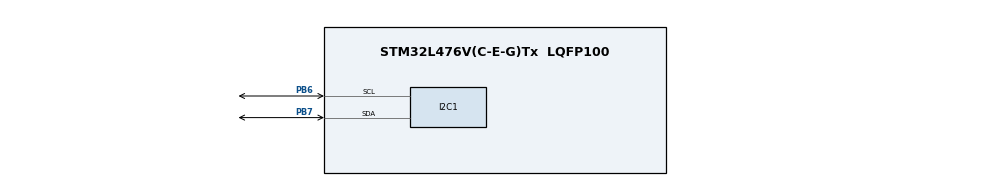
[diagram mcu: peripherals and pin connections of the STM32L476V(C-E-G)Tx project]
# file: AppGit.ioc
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Mcu.Family=STM32L4
Mcu.Name=STM32L476V(C-E-G)Tx
Mcu.Package=LQFP100
NVIC.I2C1_ER_IRQn=true\:0\:0\:false\:false\:true\:true\:true
NVIC.I2C1_EV_IRQn=true\:0\:0\:false\:false\:true\:true\:true
NVIC.PriorityGroup=NVIC_PRIORITYGROUP_4
PB6.GPIO_PuPdOD=GPIO_NOPULL
PB6.Mode=I2C
PB6.Signal=I2C1_SCL
PB7.GPIO_PuPdOD=GPIO_NOPULL
PB7.Mode=I2C
PB7.Signal=I2C1_SDA
ProjectManager.HeapSize=0x200
ProjectManager.StackSize=0x400
ProjectManager.TargetToolchain=EWARM V8.32
RCC.HSE_VALUE=8000000
RCC.HSI_VALUE=16000000
RCC.LSE_VALUE=32768
RCC.MSI_VALUE=4000000
RCC.VCOOutputFreq_Value=32000000
board=custom

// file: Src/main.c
/* USER CODE BEGIN Header */
/**
  ******************************************************************************
  * @file           : main.c
  * @brief          : Main program body
  ******************************************************************************
  * @attention
  *
  * <h2><center>&copy; Copyright (c) 2019 STMicroelectronics.
  * All rights reserved.</center></h2>
  *
  * This software component is licensed by ST under BSD 3-Clause license,
  * the "License"; You may not use this file except in compliance with the
  * License. You may obtain a copy of the License at:
  *                        opensource.org/licenses/BSD-3-Clause
  *
  ******************************************************************************
  */
/* USER CODE END Header */

#include "main.h"

/* USER CODE BEGIN Includes */
#include "bmp280.h"
/* USER CODE END Includes */

/* USER CODE BEGIN PD */
#define BMP280_I2C_ADDRESS_0 0x76
#define BMP280_I2C_ADDRESS_1 0x77
/* USER CODE END PD */

I2C_HandleTypeDef hi2c1;

/* USER CODE BEGIN PV */
BMP280_HandleTypedef bmp280;

float pressure, temperature, humidity;

uint16_t size;
uint8_t Data[256];

bool bme280p;
/* USER CODE END PV */

void SystemClock_Config(void);
static void MX_GPIO_Init(void);
static void MX_I2C1_Init(void);
/* USER CODE BEGIN PFP */
static void MX_BMP_Init(void);
/* USER CODE END PFP */

int main(void)
{

  /* MCU Configuration--------------------------------------------------------*/

  /* Reset of all peripherals, Initializes the Flash interface and the Systick. */
  HAL_Init();

  /* Configure the system clock */
  SystemClock_Config();

  /* Initialize all configured peripherals */
  MX_GPIO_Init();
  MX_I2C1_Init();
  /* USER CODE BEGIN 2 */
  MX_BMP_Init();

  /* USER CODE END 2 */

  /* Infinite loop */
  while (1)
  {
    if (!bmp280_read_float_it(&bmp280, &temperature, &pressure, &humidity))
    {
//      printf("Temperature/pressure reading failed\n");
    }
    printf("     Temperature: %.2f \n Pressure : %.2f Pa\n Humidity: %.2f \n", temperature , pressure , humidity);
    HAL_Delay(2000);
    printf("\n");
  }
}
void SystemClock_Config(void)
{
  RCC_OscInitTypeDef RCC_OscInitStruct = {0};
  RCC_ClkInitTypeDef RCC_ClkInitStruct = {0};
  RCC_PeriphCLKInitTypeDef PeriphClkInit = {0};

  /** Initializes the CPU, AHB and APB busses clocks
  */
  RCC_OscInitStruct.OscillatorType = RCC_OSCILLATORTYPE_MSI;
  RCC_OscInitStruct.MSIState = RCC_MSI_ON;
  RCC_OscInitStruct.MSICalibrationValue = 0;
  RCC_OscInitStruct.MSIClockRange = RCC_MSIRANGE_6;
  RCC_OscInitStruct.PLL.PLLState = RCC_PLL_NONE;
  if (HAL_RCC_OscConfig(&RCC_OscInitStruct) != HAL_OK)
  {
    Error_Handler();
  }
  /** Initializes the CPU, AHB and APB busses clocks
  */
  RCC_ClkInitStruct.ClockType = RCC_CLOCKTYPE_HCLK|RCC_CLOCKTYPE_SYSCLK
                              |RCC_CLOCKTYPE_PCLK1|RCC_CLOCKTYPE_PCLK2;
  RCC_ClkInitStruct.SYSCLKSource = RCC_SYSCLKSOURCE_MSI;
  RCC_ClkInitStruct.AHBCLKDivider = RCC_SYSCLK_DIV1;
  RCC_ClkInitStruct.APB1CLKDivider = RCC_HCLK_DIV1;
  RCC_ClkInitStruct.APB2CLKDivider = RCC_HCLK_DIV1;

  if (HAL_RCC_ClockConfig(&RCC_ClkInitStruct, FLASH_LATENCY_0) != HAL_OK)
  {
    Error_Handler();
  }
  PeriphClkInit.PeriphClockSelection = RCC_PERIPHCLK_I2C1;
  PeriphClkInit.I2c1ClockSelection = RCC_I2C1CLKSOURCE_PCLK1;
  if (HAL_RCCEx_PeriphCLKConfig(&PeriphClkInit) != HAL_OK)
  {
    Error_Handler();
  }
  /** Configure the main internal regulator output voltage
  */
  if (HAL_PWREx_ControlVoltageScaling(PWR_REGULATOR_VOLTAGE_SCALE1) != HAL_OK)
  {
    Error_Handler();
  }
}

static void MX_I2C1_Init(void)
{

  hi2c1.Instance = I2C1;
  hi2c1.Init.Timing = 0x00000E14;
  hi2c1.Init.OwnAddress1 = 0;
  hi2c1.Init.AddressingMode = I2C_ADDRESSINGMODE_7BIT;
  hi2c1.Init.DualAddressMode = I2C_DUALADDRESS_DISABLE;
  hi2c1.Init.OwnAddress2 = 0;
  hi2c1.Init.OwnAddress2Masks = I2C_OA2_NOMASK;
  hi2c1.Init.GeneralCallMode = I2C_GENERALCALL_DISABLE;
  hi2c1.Init.NoStretchMode = I2C_NOSTRETCH_DISABLE;
  if (HAL_I2C_Init(&hi2c1) != HAL_OK)
  {
    Error_Handler();
  }
  /** Configure Analogue filter
  */
  if (HAL_I2CEx_ConfigAnalogFilter(&hi2c1, I2C_ANALOGFILTER_ENABLE) != HAL_OK)
  {
    Error_Handler();
  }
  /** Configure Digital filter
  */
  if (HAL_I2CEx_ConfigDigitalFilter(&hi2c1, 0) != HAL_OK)
  {
    Error_Handler();
  }

}

static void MX_GPIO_Init(void)
{

  /* GPIO Ports Clock Enable */
  __HAL_RCC_GPIOB_CLK_ENABLE();

}

/* USER CODE BEGIN 4 */
static void MX_BMP_Init(void)
{
  bmp280_init_default_params(&bmp280.params);
  bmp280.addr = BMP280_I2C_ADDRESS_1;
  bmp280.i2c = &hi2c1;

  while (!bmp280_init(&bmp280, &bmp280.params))
  {
    printf("BMP280 initialization failed\n");
    HAL_Delay(2000);
  }
  bme280p = bmp280.id == BMP280_CHIP_ID;
  if (bme280p == true)
  {
    printf("BMP280: found BMP280\n");
  }
  else
  {
    printf("BMP280: found BME280\n");
  }
}

//void I2C1_EV_IRQHandler(void)
//{
//  /* USER CODE BEGIN I2C1_EV_IRQn 0 */
//
//  /* USER CODE END I2C1_EV_IRQn 0 */
//  HAL_I2C_EV_IRQHandler(&hi2c1);
//  /* USER CODE BEGIN I2C1_EV_IRQn 1 */
//  /* USER CODE END I2C1_EV_IRQn 1 */
//}

void HAL_I2C_MemRxCpltCallback(I2C_HandleTypeDef *hi2c)
{
  printf("HAL_I2C_MemRxCpltCallback\n");
}
/* USER CODE END 4 */

void Error_Handler(void)
{
}

/************************ (C) COPYRIGHT STMicroelectronics *****END OF FILE****/
